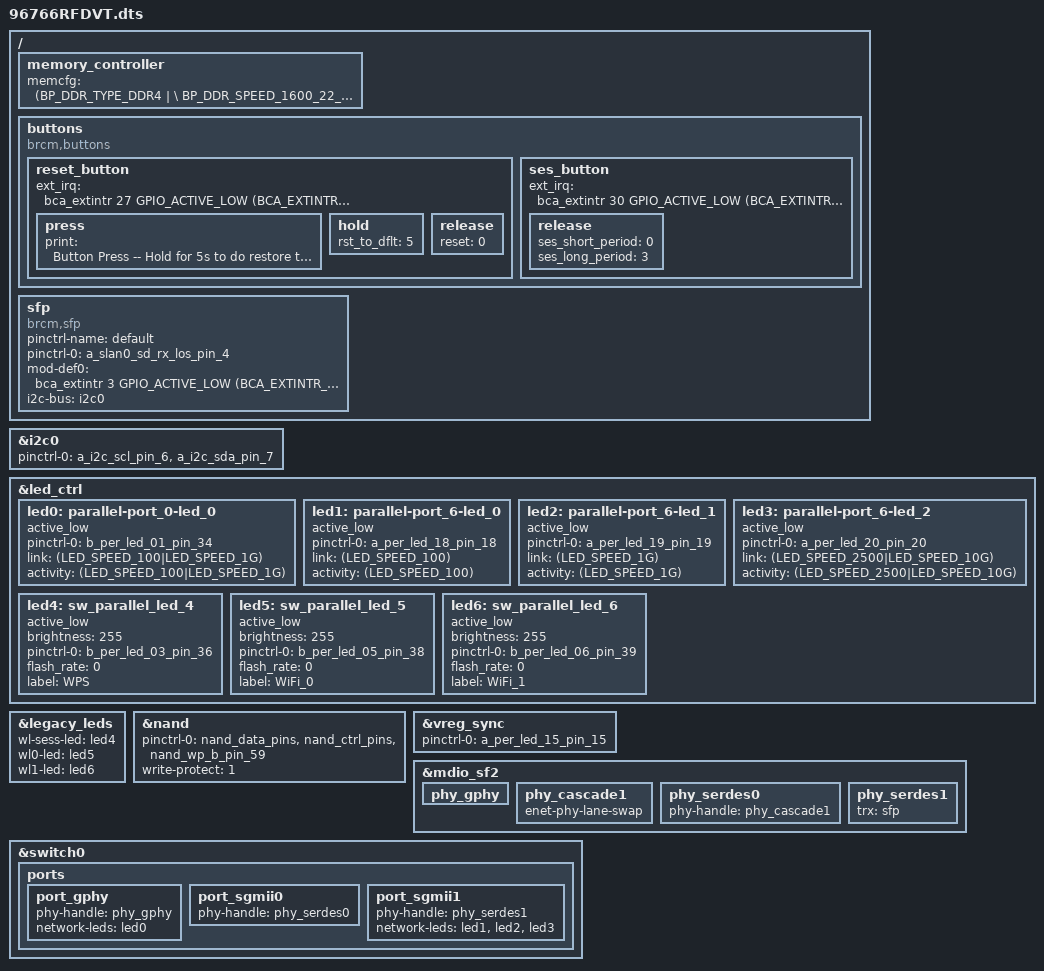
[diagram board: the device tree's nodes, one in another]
#include "6766.dtsi"

/ {
	memory_controller {
		memcfg = <(BP_DDR_TYPE_DDR4       | \
			BP_DDR_SPEED_1600_22_22_22    | \
			BP_DDR_TOTAL_SIZE_1024MB      | \
			BP_DDR_DEVICE_WIDTH_16        | \
			BP_DDR_TOTAL_WIDTH_16BIT      | \
			BP_DDR_6766_DEFAULT           | \
			BP_DDR_CONFIG_DEBUG)>;
	};

	buttons {
		compatible = "brcm,buttons";

		reset_button {
			ext_irq = <&bca_extintr 27 GPIO_ACTIVE_LOW (BCA_EXTINTR_TYPE_LOW_LEVEL | BCA_EXTINTR_TYPE_SENSE_EDGE)>;
			press {
				print = "Button Press -- Hold for 5s to do restore to default";
			};
			hold {
				rst_to_dflt = <5>;
			};
			release {
				reset = <0>;
			};
		};

		ses_button {
			ext_irq = <&bca_extintr 30 GPIO_ACTIVE_LOW (BCA_EXTINTR_TYPE_LOW_LEVEL | BCA_EXTINTR_TYPE_SENSE_EDGE)>;
			release {
				ses_short_period = <0>;
				ses_long_period = <3>;
			};
		};
	};

	sfp: sfp {
		compatible = "brcm,sfp";
		pinctrl-name = "default";
		pinctrl-0 = <&a_slan0_sd_rx_los_pin_4>;
		mod-def0 = <&bca_extintr 3 GPIO_ACTIVE_LOW (BCA_EXTINTR_TYPE_BOTH_EDGE | BCA_EXTINTR_TYPE_SENSE_EDGE)>;
		i2c-bus = <&i2c0>;
		status = "okay";
	};
};

&i2c0 {
	pinctrl-names = "default";
	pinctrl-0 = <&a_i2c_scl_pin_6 &a_i2c_sda_pin_7>;
	status = "okay";
};

&led_ctrl {
	led0: parallel-port_0-led_0 {
		active_low;
		pinctrl-0 = <&b_per_led_01_pin_34>;
		link = <(LED_SPEED_100|LED_SPEED_1G)>;
		activity = <(LED_SPEED_100|LED_SPEED_1G)>;
		status="okay";
	};

	led1: parallel-port_6-led_0 {
		active_low;
		pinctrl-0 = <&a_per_led_18_pin_18>;
		link = <(LED_SPEED_100)>;
		activity = <(LED_SPEED_100)>;
		status="okay";
	};

	led2: parallel-port_6-led_1 {
		active_low;
		pinctrl-0 = <&a_per_led_19_pin_19>;
		link = <(LED_SPEED_1G)>;
		activity = <(LED_SPEED_1G)>;
		status="okay";
	};

	led3: parallel-port_6-led_2 {
		active_low;
		pinctrl-0 = <&a_per_led_20_pin_20>;
		link = <(LED_SPEED_2500|LED_SPEED_10G)>;
		activity = <(LED_SPEED_2500|LED_SPEED_10G)>;
		status="okay";
	};

	led4: sw_parallel_led_4 {
		active_low;
		brightness = <255>;
		pinctrl-0 = <&b_per_led_03_pin_36>;
		flash_rate = <0>;
		status = "okay";
		label = "WPS";
	};

	led5: sw_parallel_led_5 {
		active_low;
		brightness = <255>;
		pinctrl-0 = <&b_per_led_05_pin_38>;
		flash_rate = <0>;
		status = "okay";
		label = "WiFi_0";
	};

	led6: sw_parallel_led_6 {
		active_low;
		brightness = <255>;
		pinctrl-0 = <&b_per_led_06_pin_39>;
		flash_rate = <0>;
		status = "okay";
		label = "WiFi_1";
	};
};

&legacy_leds {
	wl-sess-led = <&led4>;
	wl0-led = <&led5>;
	wl1-led = <&led6>;
};

&nand {
	pinctrl-0 = <&nand_data_pins &nand_ctrl_pins &nand_wp_b_pin_59>;
	write-protect = <1>;
	status = "okay";
};

&vreg_sync {
	pinctrl-0 = <&a_per_led_15_pin_15>;
	pinctrl-names = "default";
	status="okay";
};

&mdio_sf2 {
	/* Port PHY mapping:
	        port_imp -8#0- port_gphy <----> phy_gphy
	                  # 5- port_sgmii0 <--> phy_serdes0 - phy_cascade1
	                  ##6- port_sgmii1 <--> phy_serdes1 - sfp
	 */
	phy_gphy {
		status = "okay";
	};
	phy_cascade1:phy_cascade1 {
		enet-phy-lane-swap;
		status = "okay";
	};
	phy_serdes0 {
		phy-handle = <&phy_cascade1>;
		status = "okay";
	};
	phy_serdes1 {
		status = "okay";
		trx = <&sfp>;
	};
};

&switch0 {

	ports {
		port_gphy {
			phy-handle = <&phy_gphy>;
			network-leds=<&led0>;
			status = "okay";
		};
		port_sgmii0 {
			phy-handle = <&phy_serdes0>;
			status = "okay";
		};
		port_sgmii1 {
			phy-handle = <&phy_serdes1>;
			network-leds=<&led1 &led2 &led3>;
			status = "okay";
		};
	};
};
